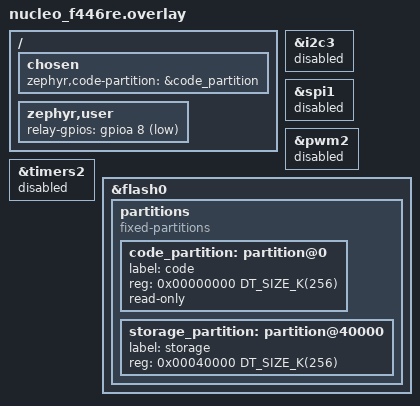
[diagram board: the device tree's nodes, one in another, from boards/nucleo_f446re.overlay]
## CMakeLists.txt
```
cmake_minimum_required(VERSION 3.20.0)
find_package(Zephyr REQUIRED HINTS $ENV{ZEPHYR_BASE})
project(grid_monitor)

target_sources(app PRIVATE
	src/main.c
	src/cfg.c
	src/cycle.c
	src/dsp.c
	src/fft_port.c
	src/sampler.c
	src/protect.c
	src/dsp_task.c
	src/logstore.c
	src/telemetry.c
	src/grid_shell.c
)
target_include_directories(app PRIVATE src)
```

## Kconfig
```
# Application Kconfig: pull in the STM32 HAL modules that src/sampler.c calls
# directly. These HAL symbols have no prompt, so they can only be selected,
# not set in prj.conf.

mainmenu "Grid Monitor"

config GRID_USES_STM32_HAL
	bool
	default y
	select USE_STM32_HAL_ADC
	select USE_STM32_HAL_ADC_EX
	select USE_STM32_HAL_DMA
	select USE_STM32_HAL_DMA_EX
	select USE_STM32_HAL_TIM
	select USE_STM32_HAL_TIM_EX
	select USE_STM32_HAL_GPIO

source "Kconfig.zephyr"
```

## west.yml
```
# West manifest: lets a teammate create the whole workspace with 3 commands.
#   west init -l grid_monitor
#   west update
# It pins Zephyr and fetches only the modules this project needs
# (the full Zephyr module set is several GB).
manifest:
  remotes:
    - name: zephyrproject-rtos
      url-base: https://github.com/zephyrproject-rtos
  projects:
    - name: zephyr
      remote: zephyrproject-rtos
      revision: v4.2.0
      import:
        name-allowlist:
          - cmsis
          - cmsis_6
          - cmsis-dsp
          - hal_stm32
  self:
    path: grid_monitor
```

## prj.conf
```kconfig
# ---- floating point on the Cortex-M4F, shared by several threads ----
CONFIG_FPU=y
CONFIG_FPU_SHARING=y
CONFIG_CBPRINTF_FP_SUPPORT=y

# (STM32 HAL modules are selected in the Kconfig file of this app)

# ---- CMSIS-DSP (real FFT) ----
CONFIG_CMSIS_DSP=y
CONFIG_CMSIS_DSP_TRANSFORM=y

# ---- message passing between threads ----
CONFIG_ZBUS=y
CONFIG_ZBUS_MSG_SUBSCRIBER=y

# ---- flash log (NVS) ----
CONFIG_FLASH=y
CONFIG_FLASH_MAP=y
CONFIG_FLASH_PAGE_LAYOUT=y
CONFIG_NVS=y
CONFIG_CRC=y

# ---- UART shell, kernel inspection ("kernel threads") ----
CONFIG_SHELL=y
CONFIG_KERNEL_SHELL=y
CONFIG_THREAD_MONITOR=y
CONFIG_THREAD_NAME=y
CONFIG_THREAD_STACK_INFO=y
CONFIG_INIT_STACKS=y
CONFIG_THREAD_RUNTIME_STATS=y
CONFIG_SHELL_THREAD_PRIORITY_OVERRIDE=y
CONFIG_SHELL_THREAD_PRIORITY=5
CONFIG_SHELL_STACK_SIZE=3072

# ---- logging goes through the shell ----
CONFIG_LOG=y
CONFIG_MAIN_STACK_SIZE=2048

# ---- keep the firmware inside the 256 KB "code" partition (see overlay) ----
CONFIG_USE_DT_CODE_PARTITION=y

# ---- zbus: fixed-size buffers, no heap use from the protection thread ----
CONFIG_ZBUS_MSG_SUBSCRIBER_BUF_ALLOC_STATIC=y
CONFIG_ZBUS_MSG_SUBSCRIBER_NET_BUF_STATIC_DATA_SIZE=64
CONFIG_ZBUS_MSG_SUBSCRIBER_NET_BUF_POOL_SIZE=16
```

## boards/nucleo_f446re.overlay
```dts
/*
 * Board overlay for the Grid Monitor on the STM32 Nucleo-F446RE.
 *
 *  PA0  voltage input (ADC1 IN0)      - set up directly by src/sampler.c
 *  PA1  current input (ADC2 IN1)      - set up directly by src/sampler.c
 *
 * Relay module (active-low, 5V coil) connected DIRECTLY to PA8 (D7) -
 * NO external transistor or MOSFET.
 * PA8 LOW  (0 V) = relay IN LOW  = relay energised (load ON)
 * PA8 HIGH (3.3V) = relay IN HIGH = relay off (load OFF)
 * GPIO_ACTIVE_LOW tells Zephyr: gpio_pin_set(relay, 1) drives PA8 LOW.
 *
 *  PA5  LD2 on-board LED              - from the board's led0 alias
 *  USART2 (PA2/PA3) 115200 baud       - shell and logs through ST-LINK
 */

/* Free the pins and timer we need by switching off board peripherals
 * that would otherwise claim them. */
/delete-node/ &boot_partition;
/delete-node/ &storage_partition;
/delete-node/ &slot0_partition;
/delete-node/ &slot1_partition;
/delete-node/ &scratch_partition;

/ {
	chosen {
		zephyr,code-partition = &code_partition;
	};

	zephyr,user {
    /*
     	* Direct connection to active-low 5V relay module.
     	* PA8 LOW  = relay ON
     	* PA8 HIGH = relay OFF
     	*/
    	relay-gpios = <&gpioa 8 GPIO_ACTIVE_LOW>;
	};
};

&i2c3  { status = "disabled"; };   /* uses PA8 */
&spi1  { status = "disabled"; };   /* uses PA5 */
&pwm2  { status = "disabled"; };
&timers2 { status = "disabled"; }; /* TIM2 is the ADC sample clock */

/*
 * Flash layout (512 KB): firmware in the first 256 KB, two 128 KB sectors at
 * the end for the NVS fault log and saved settings.
 */
&flash0 {
	partitions {
		compatible = "fixed-partitions";
		#address-cells = <1>;
		#size-cells = <1>;

		code_partition: partition@0 {
			label = "code";
			reg = <0x00000000 DT_SIZE_K(256)>;
			read-only;
		};

		storage_partition: partition@40000 {
			label = "storage";
			reg = <0x00040000 DT_SIZE_K(256)>;
		};
	};
};
```

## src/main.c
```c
/*
 * Zephyr OS Smart Grid - Micro-PMU and NILM load monitor.
 * main() only initialises the pieces; the work happens in three threads:
 *   protection (prio 0)  protect.c
 *   dsp / FFT  (prio 2)  dsp_task.c
 *   telemetry  (prio 5)  telemetry.c   (+ the UART shell, also prio 5)
 */
#include <zephyr/kernel.h>
#include <zephyr/logging/log.h>
#include "app.h"
#include "sampler.h"
#include "protect.h"
#include "logstore.h"

LOG_MODULE_REGISTER(main, LOG_LEVEL_INF);

int main(void)
{
	cfg_defaults(&g_cfg);
	int rc = protect_init();

	if (rc < 0) {
		LOG_ERR("Relay initialization failed: %d", rc);
		return rc;
	}

	if (logstore_init() == 0) {
		if (logstore_load_cfg(&g_cfg)) {
			LOG_INF("configuration loaded from flash");
		} else {
			LOG_INF("no saved configuration, using defaults");
		}
	}
	g_cfg.auto_on = 1;

	rc = sampler_init();

	if (rc) {
		LOG_ERR("sampler init failed (%d) - relay stays OFF", rc);
		return rc;
	}
	rc = sampler_start();
	if (rc) {
		LOG_ERR("sampler start failed (%d) - relay stays OFF", rc);
		return rc;
	}
	protect_start();
	LOG_INF("Grid monitor running. Type: grid help");
	return 0;
}
```

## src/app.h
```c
/*
 * app.h - shared types and constants for the Grid Monitor (Micro-PMU + NILM)
 */
#ifndef APP_H_
#define APP_H_

#include <stdint.h>
#include <stdbool.h>

/* ---- sampling geometry ------------------------------------------------ */
#define BLOCK_SAMPLES   16u      /* samples per DMA half-buffer (1.5625 ms)   */
#define RING_SAMPLES    4096u    /* raw sample ring (must be a power of two)  */
#define FFT_N           2048u    /* FFT window: 10 cycles of 50 Hz @ 10.24 kHz*/
#define FS_NOMINAL_HZ   10240.0f

/* ---- appliance classes ------------------------------------------------- */
enum load_class {
	LOAD_UNKNOWN = 0,
	LOAD_NONE,
	LOAD_RESISTIVE,
	LOAD_SMPS,
	LOAD_MOTOR,
	LOAD_CLASS_COUNT
};

/* ---- trip reasons ------------------------------------------------------ */
enum trip_reason {
	TRIP_NONE = 0,
	TRIP_PEAK,      /* instantaneous over-current (or ADC clipping)  */
	TRIP_RMS,       /* RMS over-current for several cycles           */
	TRIP_THERMAL,   /* long mild overload (I^2 t style)              */
	TRIP_POLICY,    /* appliance class not allowed                   */
	TRIP_MANUAL,    /* operator command                              */
	TRIP_SENSOR,    /* sampling stopped (fail-safe)                  */
	TRIP_VOLTAGE,   /* over/under voltage                            */
	TRIP_REASON_COUNT
};

const char *load_class_str(enum load_class c);
const char *trip_reason_str(enum trip_reason r);

/* ---- one measurement per mains cycle ------------------------------------ */
struct cycle_metrics {
	uint32_t seq;
	uint32_t t_ms;
	bool     valid;      /* false = no usable mains signal                */
	uint16_t n;          /* samples in this cycle                         */
	float    freq_hz;
	float    vrms, irms; /* real units (V, A)                             */
	float    p, s, q;    /* W, VA, var (q = sqrt(S^2-P^2), non-active)    */
	float    pf;         /* signed: P / S                                 */
	float    ipeak;      /* A                                             */
	float    v_cnt_rms;  /* rms in ADC counts (for calibration)           */
	float    i_cnt_rms;
	float    ofs_v, ofs_i;
};

/* ---- features from one FFT window ------------------------------------- */
struct features {
	bool     valid;
	uint32_t t_ms;
	float    i1;         /* fundamental current, A rms                    */
	float    h3, h5, h7; /* harmonic ratios I_n / I_1                     */
	float    thd;        /* ratio (1.0 = 100 %)                           */
	float    phi1_deg;   /* + = current lags voltage                      */
	float    cosphi1;
	float    q1;         /* fundamental reactive power, var               */
	float    vrms1;      /* fundamental voltage, V rms                    */
	float    crest, form;
};

/* ---- fault log record (stored in flash) ------------------------------- */
struct fault_event {
	uint32_t t_ms;
	uint32_t seq;
	uint8_t  reason;
	uint8_t  load_class;
	uint16_t peak_counts;   /* ADC counts, set by the fast ISR trip path */
	float    value;      /* the number that caused the trip               */
	float    irms, ipeak, vrms, p, thd;
};

/* ---- persistent configuration ----------------------------------------- */
#define CFG_MAGIC    0x47524944u   /* 'GRID' */
#define CFG_VERSION  2u

struct app_cfg {
	uint32_t magic;
	uint32_t version;
	/* calibration */
	float    k_v;           /* volts per ADC count                         */
	float    k_i1;          /* load amps per ADC count with ONE turn       */
	uint32_t turns;         /* wire turns through the clamp                */
	uint32_t invert_i;      /* 1 = clamp fitted backwards                  */
	uint32_t auto_on;       /* 1 = energise relay after warm-up            */
	/* protection */
	float    i_peak_limit;  /* A, instantaneous                            */
	float    i_rms_limit;   /* A rms                                       */
	uint32_t rms_cycles;    /* cycles above limit before trip              */
	float    i_rated;       /* A rms, thermal model                        */
	float    e_max;         /* A^2*s, thermal trip level                   */
	float    v_high;        /* V rms, 0 = disabled                         */
	float    v_low;         /* V rms, 0 = disabled                         */
	uint32_t banned_mask;   /* bit (1<<class) set = class not allowed      */
	/* classifier (ILLUSTRATIVE - tune from real measurements) */
	float    t_min_irms;    /* below this = no load                        */
	float    t_thd_res;     /* resistive: THD below                        */
	float    t_pf_res;      /* resistive: |PF| at least                    */
	float    t_thd_smps;    /* SMPS: THD at least                          */
	float    t_h3_smps;     /* SMPS: h3 at least                           */
	float    t_inrush_motor;/* motor: inrush ratio at least                */
	float    t_event_w;     /* step in P that counts as an event           */
	float    t_eps_a;       /* steady-state tolerance on Irms              */
	uint32_t steady_cycles; /* cycles of steady Irms before FFT            */
	uint32_t fft_interval;  /* cycles between FFT runs while steady        */
	uint32_t debounce;      /* identical results needed to accept a class  */
	uint32_t thd_max_h;     /* highest harmonic in THD (<= 50)             */
	uint32_t crc;           /* must stay last                              */
};

extern struct app_cfg g_cfg;

void  cfg_defaults(struct app_cfg *c);
float cfg_ki(const struct app_cfg *c);   /* load amps per ADC count */

#endif /* APP_H_ */
```

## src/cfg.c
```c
#include <string.h>
#include "app.h"

struct app_cfg g_cfg;

static const char *const class_names[LOAD_CLASS_COUNT] = {
	"Unknown", "No load", "Resistive", "Switch-mode supply", "Motor/inductive"
};
static const char *const reason_names[TRIP_REASON_COUNT] = {
	"none", "peak current", "rms current", "thermal overload",
	"policy (banned appliance)", "manual", "sensor/sampling lost", "voltage"
};

const char *load_class_str(enum load_class c)
{
	return (c < LOAD_CLASS_COUNT) ? class_names[c] : "?";
}

const char *trip_reason_str(enum trip_reason r)
{
	return (r < TRIP_REASON_COUNT) ? reason_names[r] : "?";
}

void cfg_defaults(struct app_cfg *c)
{
	memset(c, 0, sizeof(*c));
	c->magic         = CFG_MAGIC;
	c->version       = CFG_VERSION;
	/* PLACEHOLDER: run "grid cal v 7.071" for 20.00 Vpp (50 Hz) AFG sine. */
	c->k_v           = 0.33f;
	/* (3.3 V / 4096) / (0.110 V per A) for a 220 ohm burden, 1 turn */
	c->k_i1          = 0.007324f;
	c->turns         = 1;
	c->invert_i      = 0;
	c->auto_on       = 1;
	c->i_peak_limit  = 14.0f;
	c->i_rms_limit   = 8.0f;
	c->rms_cycles    = 3;
	c->i_rated       = 6.0f;
	c->e_max         = 60.0f;
	c->v_high        = 0.0f;
	c->v_low         = 0.0f;
	c->banned_mask   = 0;
	c->t_min_irms    = 0.080f;
	c->t_thd_res     = 0.20f;
	c->t_pf_res      = 0.90f;
	c->t_thd_smps    = 0.20f;
	c->t_h3_smps     = 0.10f;
	c->t_inrush_motor = 1.6f;
	c->t_event_w     = 0.20f;
	c->t_eps_a       = 0.035f;
	c->steady_cycles = 3;
	c->fft_interval  = 10;
	c->debounce      = 3;
	c->thd_max_h     = 50;
}

float cfg_ki(const struct app_cfg *c)
{
	uint32_t t = c->turns ? c->turns : 1;

	return c->k_i1 / (float)t;
}
```

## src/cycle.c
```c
#include <math.h>
#include <string.h>
#include "cycle.h"

static void reset_cur(struct cycle_det *d)
{
	memset(&d->cur, 0, sizeof(d->cur));
	d->cur.imax = -1;
	d->cur.imin = 0x7fffffff;
}

void cycle_init(struct cycle_det *d)
{
	memset(d, 0, sizeof(*d));
	d->ofs_v = 2048.0f;
	d->ofs_i = 2048.0f;
	reset_cur(d);
}

static void accumulate(struct cycle_raw *c, uint16_t v, uint16_t i)
{
	c->n++;
	c->sv += v;
	c->si += i;
	c->svv += (int64_t)v * v;
	c->sii += (int64_t)i * i;
	c->svi += (int64_t)v * i;
	if ((int32_t)i > c->imax) {
		c->imax = i;
	}
	if ((int32_t)i < c->imin) {
		c->imin = i;
	}
}

enum cyc_ev cycle_push(struct cycle_det *d, uint16_t v, uint16_t i,
		       struct cycle_raw *out)
{
	enum cyc_ev ev = CYC_NONE;

	/* Phase 1: measure the bias (about 2048 counts) over ~10 cycles. */
	if (!d->warm_done) {
		d->warm_sv += v;
		d->warm_si += i;
		if (++d->warm_n >= CYC_WARM_SAMPLES) {
			d->ofs_v = (float)d->warm_sv / (float)d->warm_n;
			d->ofs_i = (float)d->warm_si / (float)d->warm_n;
			d->warm_done = true;
		}
		return CYC_NONE;
	}

	float x = (float)v - d->ofs_v;

	d->since_cross++;

	if (x <= -(float)CYC_HYST) {
		d->armed = true;
	} else if (d->armed && x >= 0.0f) {
		/* rising zero crossing: this sample starts a new cycle */
		d->armed = false;
		if (d->in_cycle && d->cur.n >= CYC_N_MIN && d->cur.n <= CYC_N_MAX) {
			*out = d->cur;
			ev = CYC_DONE;
			/* the mean over one full cycle IS the bias; smooth it */
			float mv = (float)((double)d->cur.sv / d->cur.n);
			float mi = (float)((double)d->cur.si / d->cur.n);

			d->ofs_v += 0.25f * (mv - d->ofs_v);
			d->ofs_i += 0.25f * (mi - d->ofs_i);
		}
		d->since_cross = 1;
		reset_cur(d);
		d->in_cycle = true;
	} else if (d->since_cross > CYC_NOSIG_SAMPLES) {
		d->since_cross = 0;
		d->armed = false;
		d->in_cycle = false;
		reset_cur(d);
		ev = CYC_NOSIG;
	}

	if (d->in_cycle) {
		accumulate(&d->cur, v, i);
	}
	return ev;
}

void cycle_finish(const struct cycle_raw *r, const struct app_cfg *c,
		  float fs, struct cycle_metrics *m)
{
	double n  = (double)r->n;
	double mv = (double)r->sv / n;
	double mi = (double)r->si / n;
	double vv = (double)r->svv / n - mv * mv;
	double ii = (double)r->sii / n - mi * mi;
	double vi = (double)r->svi / n - mv * mi;

	if (vv < 0.0) {
		vv = 0.0;
	}
	if (ii < 0.0) {
		ii = 0.0;
	}

	double kv = c->k_v;
	double ki = cfg_ki(c);
	double vrms = sqrt(vv) * kv;
	double irms = sqrt(ii) * ki;
	double p = vi * kv * ki * (c->invert_i ? -1.0 : 1.0);
	double s = vrms * irms;
	double pf = (s > 1e-9) ? p / s : 0.0;
	double q2 = s * s - p * p;
	double dpk = (double)r->imax - mi;

	if (mi - (double)r->imin > dpk) {
		dpk = mi - (double)r->imin;
	}
	if (pf > 1.0) {
		pf = 1.0;
	}
	if (pf < -1.0) {
		pf = -1.0;
	}

	m->valid     = true;
	m->n         = (uint16_t)r->n;
	m->freq_hz   = fs / (float)r->n;
	m->vrms      = (float)vrms;
	m->irms      = (float)irms;
	m->p         = (float)p;
	m->s         = (float)s;
	m->q         = (float)sqrt(q2 > 0.0 ? q2 : 0.0);
	m->pf        = (float)pf;
	m->ipeak     = (float)(dpk * ki);
	m->v_cnt_rms = (float)sqrt(vv);
	m->i_cnt_rms = (float)sqrt(ii);
	m->ofs_v     = (float)mv;
	m->ofs_i     = (float)mi;
}
```

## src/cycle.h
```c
/*
 * cycle.h - mains-cycle detector and per-cycle power maths.
 * Pure C: no Zephyr or hardware dependencies, so it is unit-tested on a PC.
 */
#ifndef CYCLE_H_
#define CYCLE_H_

#include <stdint.h>
#include <stdbool.h>
#include "app.h"

#define CYC_WARM_SAMPLES   2048   /* initial offset measurement           */
#define CYC_HYST           10     /* counts below zero needed to re-arm   */
#define CYC_NOSIG_SAMPLES  600    /* ~58 ms without a crossing = no mains */
#define CYC_N_MIN          150    /* 68 Hz                                */
#define CYC_N_MAX          260    /* 39 Hz                                */

struct cycle_raw {
	uint32_t n;
	int64_t  sv, si;       /* sums of raw counts                          */
	int64_t  svv, sii, svi;
	int32_t  imax, imin;
};

struct cycle_det {
	bool     warm_done;
	uint32_t warm_n;
	int64_t  warm_sv, warm_si;
	float    ofs_v, ofs_i;
	bool     armed, in_cycle;
	uint32_t since_cross;
	struct cycle_raw cur;
};

enum cyc_ev { CYC_NONE = 0, CYC_DONE, CYC_NOSIG };

void cycle_init(struct cycle_det *d);

/* Feed one simultaneous (voltage, current) sample pair of raw ADC counts. */
enum cyc_ev cycle_push(struct cycle_det *d, uint16_t v, uint16_t i,
		       struct cycle_raw *out);

/* Turn raw sums into real units. fs = actual sampling rate in Hz. */
void cycle_finish(const struct cycle_raw *r, const struct app_cfg *c,
		  float fs, struct cycle_metrics *m);

#endif
```

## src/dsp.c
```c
#include <math.h>
#include <string.h>
#include "dsp.h"

#ifndef M_PI
#define M_PI 3.14159265358979323846
#endif

static float hann[FFT_N];
static float wk_in[FFT_N];
static float wk_out[FFT_N];

void dsp_init(void)
{
	for (uint32_t n = 0; n < FFT_N; n++) {
		hann[n] = 0.5f * (1.0f - cosf(2.0f * (float)M_PI * (float)n /
					      (float)(FFT_N - 1)));
	}
	fft_port_init();
}

static inline float bin_mag(const float *X, uint32_t k)
{
	return hypotf(X[2 * k], X[2 * k + 1]);
}

/* largest magnitude among bins k-1, k, k+1 */
static uint32_t peak_bin(const float *X, uint32_t k)
{
	uint32_t best = k;
	float bm = bin_mag(X, k);

	if (k > 1 && bin_mag(X, k - 1) > bm) {
		best = k - 1;
		bm = bin_mag(X, k - 1);
	}
	if (k + 1 < FFT_N / 2 && bin_mag(X, k + 1) > bm) {
		best = k + 1;
	}
	return best;
}

/* amplitude (counts, peak) of a Hann-windowed real FFT bin */
static inline float amp(const float *X, uint32_t k)
{
	return 4.0f * bin_mag(X, k) / (float)FFT_N;
}

bool dsp_features(const uint16_t *v, const uint16_t *i, const struct app_cfg *c,
		  struct features *f)
{
	memset(f, 0, sizeof(*f));

	/* ---- time-domain stats of the current (crest / form factor) ---- */
	double sv = 0, si = 0;

	for (uint32_t n = 0; n < FFT_N; n++) {
		sv += v[n];
		si += i[n];
	}
	float mv = (float)(sv / FFT_N);
	float mi = (float)(si / FFT_N);
	double ss = 0.0, sabs = 0.0;
	float pk = 0;

	for (uint32_t n = 0; n < FFT_N; n++) {
		float d = (float)i[n] - mi;

		ss += (double)d * (double)d;
		sabs += (double)fabsf(d);
		if (fabsf(d) > pk) {
			pk = fabsf(d);
		}
	}
	float irms_c = (float)sqrt(ss / FFT_N);
	float iabs_c = (float)(sabs / (double)FFT_N);

	if (irms_c < 1.0f) {
		return false;      /* less than one count of signal */
	}
	f->crest = pk / irms_c;
	f->form = (iabs_c > 0.0f) ? irms_c / iabs_c : 0.0f;

	float sgn = c->invert_i ? -1.0f : 1.0f;

	/* ---- voltage spectrum: find the fundamental bin ---- */
	for (uint32_t n = 0; n < FFT_N; n++) {
		wk_in[n] = ((float)v[n] - mv) * hann[n];
	}
	fft_port_rfft(wk_in, wk_out);

	uint32_t kf = 10;
	float best = 0;

	for (uint32_t k = 8; k <= 12; k++) {      /* 40 .. 60 Hz */
		float m = bin_mag(wk_out, k);

		if (m > best) {
			best = m;
			kf = k;
		}
	}
	if (best < 1.0f) {
		return false;      /* no voltage fundamental */
	}
	float vre = wk_out[2 * kf], vim = wk_out[2 * kf + 1];
	float v1_counts_peak = amp(wk_out, peak_bin(wk_out, kf));

	/* ---- current spectrum ---- */
	for (uint32_t n = 0; n < FFT_N; n++) {
		wk_in[n] = sgn * ((float)i[n] - mi) * hann[n];
	}
	fft_port_rfft(wk_in, wk_out);

	float ire = wk_out[2 * kf], iim = wk_out[2 * kf + 1];
	float i1_peak = amp(wk_out, peak_bin(wk_out, kf));

	if (i1_peak < 0.5f) {
		return false;
	}
	float ki = cfg_ki(c);
	const float r2 = 0.70710678f;

	f->i1 = i1_peak * r2 * ki;
	f->vrms1 = v1_counts_peak * r2 * c->k_v;

	float hsum2 = 0.0f;
	uint32_t H = c->thd_max_h;

	if (H < 2) {
		H = 2;
	}
	if (H > 50) {
		H = 50;
	}
	for (uint32_t h = 2; h <= H; h++) {
		uint32_t k = h * kf;

		if (k + 1 >= FFT_N / 2) {
			break;
		}
		float a = amp(wk_out, peak_bin(wk_out, k));

		hsum2 += a * a;
		if (h == 3) {
			f->h3 = a / i1_peak;
		} else if (h == 5) {
			f->h5 = a / i1_peak;
		} else if (h == 7) {
			f->h7 = a / i1_peak;
		}
	}
	f->thd = sqrtf(hsum2) / i1_peak;

	/* phase: positive = current lags voltage (inductive) */
	float phi = atan2f(vim, vre) - atan2f(iim, ire);

	while (phi > (float)M_PI) {
		phi -= 2.0f * (float)M_PI;
	}
	while (phi <= -(float)M_PI) {
		phi += 2.0f * (float)M_PI;
	}
	f->phi1_deg = phi * 180.0f / (float)M_PI;
	f->cosphi1 = cosf(phi);
	f->q1 = f->vrms1 * f->i1 * sinf(phi);
	f->valid = true;
	return true;
}

enum load_class dsp_classify(const struct app_cfg *c, float irms, float pf,
			     const struct features *f, float inrush)
{
	float apf = fabsf(pf);

	if (irms < c->t_min_irms) {
		return LOAD_NONE;
	}
	if (!f || !f->valid) {
		return LOAD_UNKNOWN;
	}
	if (f->thd >= c->t_thd_smps && f->h3 >= c->t_h3_smps) {
		return LOAD_SMPS;
	}
	if (f->thd < c->t_thd_res && apf >= c->t_pf_res) {
		return LOAD_RESISTIVE;
	}
	if (f->thd < c->t_thd_smps &&
	    (apf < c->t_pf_res || inrush >= c->t_inrush_motor)) {
		return LOAD_MOTOR;
	}
	return LOAD_UNKNOWN;
}

/* ====================== transient tracker ============================= */

void tracker_init(struct tracker *t)
{
	memset(t, 0, sizeof(*t));
	t->state = TR_SETTLING;
	t->inrush = 1.0f;
	t->accepted = LOAD_UNKNOWN;
	t->cand = LOAD_UNKNOWN;
}

static void start_event(struct tracker *t, const struct cycle_metrics *m)
{
	t->state = TR_SETTLING;
	t->steady_cnt = 0;
	t->peak_since_event = m->ipeak;
	t->cand = LOAD_UNKNOWN;
	t->cand_cnt = 0;
}

void tracker_on_cycle(struct tracker *t, const struct app_cfg *c,
		      const struct cycle_metrics *m, struct tracker_out *out)
{
	memset(out, 0, sizeof(*out));
	if (!m->valid) {
		t->have_prev = false;
		t->state = TR_SETTLING;
		t->steady_cnt = 0;
		return;
	}

	float eps = c->t_eps_a;

	if (0.03f * m->irms > eps) {
		eps = 0.03f * m->irms;
	}

	if (!t->have_prev) {
		t->have_prev = true;
		start_event(t, m);
		t->prev_irms = m->irms;
		t->prev_p = m->p;
		return;
	}

	/* "no load" detection (needs several cycles in a row) */
	if (m->irms < c->t_min_irms) {
		if (++t->none_cnt >= 5 && t->accepted != LOAD_NONE) {
			t->accepted = LOAD_NONE;
			out->class_changed = true;
		}
	} else {
		t->none_cnt = 0;
	}

	float dp = m->p - t->prev_p;

	if (fabsf(dp) > c->t_event_w) {
		start_event(t, m);
		out->event = true;
	} else if (t->state == TR_SETTLING) {
		if (m->ipeak > t->peak_since_event) {
			t->peak_since_event = m->ipeak;
		}
		if (fabsf(m->irms - t->prev_irms) < eps) {
			t->steady_cnt++;
		} else {
			t->steady_cnt = 0;
		}
		if (t->steady_cnt >= c->steady_cycles) {
			t->state = TR_STEADY;
			t->steady_irms = m->irms;
			t->inrush = (m->irms < c->t_min_irms || m->ipeak < 1e-3f) ?
				    1.0f : t->peak_since_event / m->ipeak;
			t->since_fft = c->fft_interval;   /* run FFT at once */
			out->need_fft = true;
		}
	} else { /* STEADY */
		float lim = 3.0f * eps;

		if (0.15f * t->steady_irms > lim) {
			lim = 0.15f * t->steady_irms;
		}
		if (fabsf(m->irms - t->steady_irms) > lim) {
			start_event(t, m);
			out->event = true;
		} else if (++t->since_fft >= c->fft_interval) {
			t->since_fft = 0;
			out->need_fft = true;
		}
	}
	t->prev_irms = m->irms;
	t->prev_p = m->p;
}

void tracker_on_features(struct tracker *t, const struct app_cfg *c,
			 const struct cycle_metrics *m, const struct features *f,
			 struct tracker_out *out)
{
	memset(out, 0, sizeof(*out));
	if (t->state != TR_STEADY) {
		return;     /* never classify during a transient */
	}
	enum load_class cls = dsp_classify(c, m->irms, m->pf, f, t->inrush);

	if (cls == t->cand) {
		t->cand_cnt++;
	} else {
		t->cand = cls;
		t->cand_cnt = 1;
	}
	if (t->cand_cnt >= c->debounce && t->cand != t->accepted) {
		t->accepted = t->cand;
		out->class_changed = true;
	}
}
```

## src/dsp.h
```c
/*
 * dsp.h - FFT features, appliance classifier and transient tracker.
 * Pure C (the FFT itself is behind fft_port.h) so it is unit-tested on a PC.
 */
#ifndef DSP_H_
#define DSP_H_

#include <stdint.h>
#include <stdbool.h>
#include "app.h"

/* The FFT back-end. Real FFT of FFT_N floats.
 * `in` may be destroyed. `out` is CMSIS "packed" format:
 *   out[0] = Re X[0], out[1] = Re X[N/2], then out[2k], out[2k+1] = Re, Im X[k]
 */
void fft_port_init(void);
void fft_port_rfft(float *in, float *out);

void dsp_init(void);

/* Compute features from FFT_N simultaneous raw samples. fs in Hz. */
bool dsp_features(const uint16_t *v, const uint16_t *i, const struct app_cfg *c,
		  struct features *f);

/* Pure classification rule. inrush = start-up peak / steady peak. */
enum load_class dsp_classify(const struct app_cfg *c, float irms, float pf,
			     const struct features *f, float inrush);

/* ---- transient tracker ------------------------------------------------ */
enum tr_state { TR_SETTLING = 0, TR_STEADY };

struct tracker {
	enum tr_state state;
	bool     have_prev;
	float    prev_irms, prev_p;
	float    steady_irms;
	uint32_t steady_cnt;
	uint32_t since_fft;
	uint32_t none_cnt;
	float    peak_since_event;
	float    inrush;
	enum load_class cand;
	uint32_t cand_cnt;
	enum load_class accepted;
};

struct tracker_out {
	bool need_fft;       /* run an FFT on the latest window now           */
	bool event;          /* a step change was detected                    */
	bool class_changed;  /* tracker->accepted changed                     */
};

void tracker_init(struct tracker *t);
void tracker_on_cycle(struct tracker *t, const struct app_cfg *c,
		      const struct cycle_metrics *m, struct tracker_out *out);
void tracker_on_features(struct tracker *t, const struct app_cfg *c,
			 const struct cycle_metrics *m, const struct features *f,
			 struct tracker_out *out);

#endif
```

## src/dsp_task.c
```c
/*
 * dsp_task.c - medium-priority thread: receives per-cycle metrics over zbus,
 * runs the transient tracker, takes a 2048-sample window when asked, computes
 * the FFT features and classifies the appliance.
 */
#include <zephyr/kernel.h>
#include <zephyr/logging/log.h>
#include "protect.h"
#include "sampler.h"
#include "dsp.h"

LOG_MODULE_REGISTER(dsp, LOG_LEVEL_INF);

ZBUS_MSG_SUBSCRIBER_DEFINE(dsp_sub);

static struct tracker trk;
static uint16_t wv[FFT_N], wi[FFT_N];

static void announce(const struct cycle_metrics *m)
{
	enum load_class cls = trk.accepted;

	protect_set_class(cls);
	LOG_INF("Load: %s  (Irms %d mA, P %d W, PF x100 %d)", load_class_str(cls),
		(int)(m->irms * 1000.0f), (int)m->p, (int)(m->pf * 100.0f));
	if ((g_cfg.banned_mask >> cls) & 1u) {
		LOG_WRN("Policy: appliance class not allowed -> trip");
		(void)protect_trip(TRIP_POLICY, (float)cls);
	}
}

static void dsp_thread(void *a, void *b, void *c)
{
	ARG_UNUSED(a); ARG_UNUSED(b); ARG_UNUSED(c);
	const struct zbus_channel *chan;
	struct cycle_metrics m;

	k_thread_name_set(NULL, "dsp_fft");
	dsp_init();
	tracker_init(&trk);

	for (;;) {
		if (zbus_sub_wait_msg(&dsp_sub, &chan, &m, K_FOREVER) != 0) {
			continue;
		}
		struct tracker_out o;

		tracker_on_cycle(&trk, &g_cfg, &m, &o);
		if (o.class_changed) {
			announce(&m);
		}
		if (o.need_fft && sampler_copy_window(wv, wi, FFT_N)) {
			struct features f;

			if (dsp_features(wv, wi, &g_cfg, &f)) {
				f.t_ms = k_uptime_get_32();
				protect_set_features(&f);
				protect_count_feature_run();
				tracker_on_features(&trk, &g_cfg, &m, &f, &o);
				if (o.class_changed) {
					announce(&m);
				}
			}
		}
	}
}

K_THREAD_DEFINE(dsp_tid, 4096, dsp_thread, NULL, NULL, NULL,
		K_PRIO_PREEMPT(2), 0, 0);
```

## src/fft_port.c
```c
/* FFT back-end using ARM CMSIS-DSP (Zephyr module cmsis-dsp). */
#include <arm_math.h>
#include "dsp.h"

static arm_rfft_fast_instance_f32 inst;

void fft_port_init(void)
{
	arm_rfft_fast_init_f32(&inst, FFT_N);
}

void fft_port_rfft(float *in, float *out)
{
	arm_rfft_fast_f32(&inst, in, out, 0);
}
```

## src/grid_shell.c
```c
/*
 * grid_shell.c - the "grid" command family on the UART shell.
 *   grid help
 */
#include <zephyr/kernel.h>
#include <zephyr/shell/shell.h>
#include <stdlib.h>
#include <string.h>
#include <stddef.h>
#include "app.h"
#include "protect.h"
#include "sampler.h"
#include "logstore.h"

/* ------------------------------------------------------------ status -- */

static int cmd_status(const struct shell *sh, size_t argc, char **argv)
{
	struct cycle_metrics m;
	struct features f;
	enum load_class cls;

	protect_get_snapshot(&m, &f, &cls);
	if (protect_is_tripped()) {
		shell_print(sh, "relay      : OFF - TRIPPED (%s). Use 'grid reset' after fixing the cause.",
			    trip_reason_str(protect_last_reason()));
	} else {
		shell_print(sh, "relay      : %s", protect_relay_state() ? "ON (load energised)" : "OFF");
	}
	if (!m.valid) {
		shell_print(sh, "mains      : no usable voltage signal yet");
	} else {
		shell_print(sh, "mains      : %.1f V rms, %.2f Hz", (double)m.vrms, (double)m.freq_hz);
		shell_print(sh, "current    : %.3f A rms, %.3f A peak", (double)m.irms, (double)m.ipeak);
		shell_print(sh, "power      : P %.1f W   S %.1f VA   Q(non-active) %.1f var   PF %.3f",
			    (double)m.p, (double)m.s, (double)m.q, (double)m.pf);
		if (m.p < -0.2f * m.s && m.s > 5.0f) {
			shell_warn(sh, "P is negative: clamp is probably backwards (try: grid cfg set invert_i 1)");
		}
	}
	shell_print(sh, "load class : %s", load_class_str(cls));
	if (f.valid) {
		shell_print(sh, "FFT        : I1 %.3f A  h3 %.2f h5 %.2f h7 %.2f  THD %.1f %%",
			    (double)f.i1, (double)f.h3, (double)f.h5, (double)f.h7, (double)(f.thd * 100.0f));
	}
	return 0;
}

static int cmd_feat(const struct shell *sh, size_t argc, char **argv)
{
	struct features f;

	protect_get_snapshot(NULL, &f, NULL);
	if (!f.valid) {
		shell_print(sh, "no FFT result yet (needs a steady load)");
		return 0;
	}
	shell_print(sh, "I1 %.4f A   Vrms1 %.1f V", (double)f.i1, (double)f.vrms1);
	shell_print(sh, "h3 %.3f  h5 %.3f  h7 %.3f  THD %.3f", (double)f.h3, (double)f.h5,
		    (double)f.h7, (double)f.thd);
	shell_print(sh, "phi1 %.1f deg (+ = current lags)  cos(phi1) %.3f  Q1 %.1f var",
		    (double)f.phi1_deg, (double)f.cosphi1, (double)f.q1);
	shell_print(sh, "crest %.2f  form %.2f", (double)f.crest, (double)f.form);
	return 0;
}

static int cmd_stats(const struct shell *sh, size_t argc, char **argv)
{
	struct sampler_stats s;
	struct protect_stats p;

	sampler_get_stats(&s);
	protect_get_stats(&p);
	shell_print(sh, "timer clock %u Hz, ARR %u, sampling rate %.3f Hz", s.timer_hz, s.arr,
		    (double)sampler_fs());
	shell_print(sh, "blocks %u  adc_err %u  dma_err %u  fast_trips %u", s.blocks, s.adc_err,
		    s.dma_err, s.fast_trips);
	shell_print(sh, "cycles %u  no-signal %u  ring overruns %u  fft runs %u", p.cycles, p.nosig,
		    p.overruns, p.feature_runs);
	return 0;
}

/* -------------------------------------------------------------- dump -- */

static uint16_t dv[FFT_N], di[FFT_N];

static int cmd_dump(const struct shell *sh, size_t argc, char **argv)
{
	uint32_t n = 1024;

	if (argc > 1) {
		n = (uint32_t)strtoul(argv[1], NULL, 10);
	}
	if (n < 16 || n > FFT_N) {
		shell_error(sh, "n must be 16..%u", (unsigned)FFT_N);
		return -EINVAL;
	}
	if (!sampler_copy_window(dv, di, n)) {
		shell_error(sh, "not enough samples yet, try again");
		return -EAGAIN;
	}
	shell_print(sh, "DUMP BEGIN fs=%.3f n=%u kv=%.6f ki=%.6f", (double)sampler_fs(),
		    (unsigned)n, (double)g_cfg.k_v, (double)cfg_ki(&g_cfg));
	for (uint32_t k = 0; k < n; k++) {
		shell_print(sh, "%u,%u", dv[k], di[k]);
	}
	shell_print(sh, "DUMP END");
	return 0;
}

/* --------------------------------------------------------- fault log -- */

static int cmd_fault_log(const struct shell *sh, size_t argc, char **argv)
{
	if (argc > 1 && strcmp(argv[1], "clear") == 0) {
		int rc = logstore_clear_faults();

		shell_print(sh, rc ? "clear failed (%d)" : "fault log cleared", rc);
		return rc;
	}
	uint32_t total = logstore_fault_count();

	shell_print(sh, "fault log: %u event(s) recorded in total (newest first)", total);
	for (uint32_t k = 0; k < 32; k++) {
		struct fault_event e;

		if (logstore_read_fault(k, &e) != 0) {
			break;
		}
		shell_print(sh, "#%u  t=%u ms  %s  | load=%s  value=%.3f  Irms=%.3f A  Ipeak=%.3f A  Vrms=%.1f V  P=%.1f W  THD=%.2f",
			    e.seq, e.t_ms, trip_reason_str((enum trip_reason)e.reason),
			    load_class_str((enum load_class)e.load_class), (double)e.value,
			    (double)e.irms, (double)e.ipeak, (double)e.vrms, (double)e.p, (double)e.thd);
	}
	return 0;
}

/* ------------------------------------------------------------- relay -- */

static int cmd_on(const struct shell *sh, size_t argc, char **argv)
{
	if (!protect_relay_on()) {
		shell_error(sh, "a trip is latched: use 'grid reset' after fixing the cause");
		return -EPERM;
	}
	shell_print(sh, "relay ON");
	return 0;
}

static int cmd_off(const struct shell *sh, size_t argc, char **argv)
{
	protect_relay_off();
	shell_print(sh, "relay OFF");
	return 0;
}

static int cmd_reset(const struct shell *sh, size_t argc, char **argv)
{
	protect_reset();
	shell_print(sh, "trip cleared, relay ON");
	return 0;
}

static int cmd_trip(const struct shell *sh, size_t argc, char **argv)
{
	(void)protect_trip(TRIP_MANUAL, 0.0f);
	shell_print(sh, "manual trip issued");
	return 0;
}

/* --------------------------------------------------------- calibrate -- */

static int cmd_cal(const struct shell *sh, size_t argc, char **argv)
{
	struct cycle_metrics m;

	if (argc != 3) {
		shell_error(sh, "usage: grid cal v <volts_rms> | grid cal i <amps_rms>");
		return -EINVAL;
	}
	float val = strtof(argv[2], NULL);

	protect_get_snapshot(&m, NULL, NULL);
	if (!m.valid || val <= 0.0f) {
		shell_error(sh, "need a valid mains signal and a positive value");
		return -EINVAL;
	}
	if (argv[1][0] == 'v') {
		if (m.v_cnt_rms < 5.0f) {
			shell_error(sh, "voltage signal too small");
			return -EINVAL;
		}
		g_cfg.k_v = val / m.v_cnt_rms;
		shell_print(sh, "k_v = %.6f V/count  (read the multimeter, then 'grid cfg save')",
			    (double)g_cfg.k_v);
	} else if (argv[1][0] == 'i') {
		if (m.i_cnt_rms < 2.0f) {
			shell_error(sh, "current signal too small - connect a known load");
			return -EINVAL;
		}
		g_cfg.k_i1 = val * (float)g_cfg.turns / m.i_cnt_rms;
		shell_print(sh, "k_i1 = %.6f A/count at 1 turn  (turns = %u)", (double)g_cfg.k_i1,
			    (unsigned)g_cfg.turns);
	} else {
		return -EINVAL;
	}
	return 0;
}

/* --------------------------------------------------------------- cfg -- */

enum ft { T_F, T_U };
struct field {
	const char *name;
	enum ft t;
	size_t off;
};
#define FF(n) { #n, T_F, offsetof(struct app_cfg, n) }
#define FU(n) { #n, T_U, offsetof(struct app_cfg, n) }

static const struct field fields[] = {
	FF(k_v), FF(k_i1), FU(turns), FU(invert_i), FU(auto_on),
	FF(i_peak_limit), FF(i_rms_limit), FU(rms_cycles), FF(i_rated), FF(e_max),
	FF(v_high), FF(v_low), FU(banned_mask),
	FF(t_min_irms), FF(t_thd_res), FF(t_pf_res), FF(t_thd_smps), FF(t_h3_smps),
	FF(t_inrush_motor), FF(t_event_w), FF(t_eps_a),
	FU(steady_cycles), FU(fft_interval), FU(debounce), FU(thd_max_h),
};

static void show_field(const struct shell *sh, const struct field *f)
{
	const uint8_t *base = (const uint8_t *)&g_cfg;

	if (f->t == T_F) {
		shell_print(sh, "  %-16s = %.6g", f->name, (double)*(const float *)(base + f->off));
	} else {
		shell_print(sh, "  %-16s = %u", f->name, *(const uint32_t *)(base + f->off));
	}
}

static int cmd_cfg(const struct shell *sh, size_t argc, char **argv)
{
	if (argc < 2) {
		shell_error(sh, "usage: grid cfg show | set <name> <value> | save | default");
		return -EINVAL;
	}
	if (strcmp(argv[1], "show") == 0) {
		for (size_t k = 0; k < ARRAY_SIZE(fields); k++) {
			show_field(sh, &fields[k]);
		}
		return 0;
	}
	if (strcmp(argv[1], "default") == 0) {
		cfg_defaults(&g_cfg);
		shell_print(sh, "defaults loaded (not saved yet)");
		return 0;
	}
	if (strcmp(argv[1], "save") == 0) {
		int rc = logstore_save_cfg(&g_cfg);

		shell_print(sh, rc ? "save failed (%d)" : "configuration saved to flash", rc);
		return rc;
	}
	if (strcmp(argv[1], "set") == 0 && argc == 4) {
		for (size_t k = 0; k < ARRAY_SIZE(fields); k++) {
			if (strcmp(argv[2], fields[k].name) != 0) {
				continue;
			}
			uint8_t *base = (uint8_t *)&g_cfg;

			if (fields[k].t == T_F) {
				*(float *)(base + fields[k].off) = strtof(argv[3], NULL);
			} else {
				*(uint32_t *)(base + fields[k].off) = (uint32_t)strtoul(argv[3], NULL, 0);
			}
			/* keep a few values inside safe ranges */
			if (g_cfg.turns < 1) { g_cfg.turns = 1; }
			if (g_cfg.turns > 50) { g_cfg.turns = 50; }
			if (g_cfg.thd_max_h < 2) { g_cfg.thd_max_h = 2; }
			if (g_cfg.thd_max_h > 50) { g_cfg.thd_max_h = 50; }
			if (g_cfg.steady_cycles < 2) { g_cfg.steady_cycles = 2; }
			if (g_cfg.fft_interval < 1) { g_cfg.fft_interval = 1; }
			if (g_cfg.debounce < 1) { g_cfg.debounce = 1; }
			if (g_cfg.rms_cycles < 1) { g_cfg.rms_cycles = 1; }
			show_field(sh, &fields[k]);
			return 0;
		}
		shell_error(sh, "unknown field '%s' (see: grid cfg show)", argv[2]);
		return -EINVAL;
	}
	shell_error(sh, "usage: grid cfg show | set <name> <value> | save | default");
	return -EINVAL;
}

/* ------------------------------------------------------------ policy -- */

static int class_from_name(const char *s)
{
	if (strcmp(s, "resistive") == 0) { return LOAD_RESISTIVE; }
	if (strcmp(s, "smps") == 0)      { return LOAD_SMPS; }
	if (strcmp(s, "motor") == 0)     { return LOAD_MOTOR; }
	if (strcmp(s, "unknown") == 0)   { return LOAD_UNKNOWN; }
	return -1;
}

static int cmd_policy(const struct shell *sh, size_t argc, char **argv)
{
	if (argc >= 2 && strcmp(argv[1], "clear") == 0) {
		g_cfg.banned_mask = 0;
	} else if (argc == 3 && (strcmp(argv[1], "ban") == 0 || strcmp(argv[1], "allow") == 0)) {
		int c = class_from_name(argv[2]);

		if (c < 0) {
			shell_error(sh, "class must be: resistive | smps | motor | unknown");
			return -EINVAL;
		}
		if (argv[1][0] == 'b') {
			g_cfg.banned_mask |= (1u << c);
		} else {
			g_cfg.banned_mask &= ~(1u << c);
		}
	} else if (argc != 2 || strcmp(argv[1], "show") != 0) {
		shell_error(sh, "usage: grid policy show | ban <class> | allow <class> | clear");
		return -EINVAL;
	}
	shell_print(sh, "banned classes:");
	bool any = false;

	for (int c = 0; c < LOAD_CLASS_COUNT; c++) {
		if ((g_cfg.banned_mask >> c) & 1u) {
			shell_print(sh, "  %s", load_class_str((enum load_class)c));
			any = true;
		}
	}
	if (!any) {
		shell_print(sh, "  (none)");
	}
	return 0;
}

/* -------------------------------------------------------------- help -- */

static int cmd_help(const struct shell *sh, size_t argc, char **argv)
{
	shell_print(sh,
		"grid status              live power numbers, relay and load class\n"
		"grid feat                FFT features (harmonics, THD, phase)\n"
		"grid stats               sampler and thread statistics\n"
		"grid dump [n]            raw samples as CSV (for tools/analyze_dump.py)\n"
		"grid fault_log [clear]   trip history stored in flash\n"
		"grid on | off | reset    relay control (reset clears a latched trip)\n"
		"grid trip                manual trip (test)\n"
		"grid cal v <V>           calibrate voltage against a multimeter\n"
		"grid cal i <A>           calibrate current against a known load\n"
		"grid cfg show|set|save|default   settings and thresholds\n"
		"grid policy show|ban|allow|clear <resistive|smps|motor|unknown>\n"
		"kernel threads           thread priorities, stack and CPU use");
	return 0;
}

SHELL_STATIC_SUBCMD_SET_CREATE(sub_grid,
	SHELL_CMD_ARG(help, NULL, "list commands", cmd_help, 1, 0),
	SHELL_CMD_ARG(status, NULL, "live status", cmd_status, 1, 0),
	SHELL_CMD_ARG(feat, NULL, "FFT features", cmd_feat, 1, 0),
	SHELL_CMD_ARG(stats, NULL, "statistics", cmd_stats, 1, 0),
	SHELL_CMD_ARG(dump, NULL, "dump [n]: raw samples", cmd_dump, 1, 1),
	SHELL_CMD_ARG(fault_log, NULL, "fault_log [clear]", cmd_fault_log, 1, 1),
	SHELL_CMD_ARG(on, NULL, "relay on", cmd_on, 1, 0),
	SHELL_CMD_ARG(off, NULL, "relay off", cmd_off, 1, 0),
	SHELL_CMD_ARG(reset, NULL, "clear trip, relay on", cmd_reset, 1, 0),
	SHELL_CMD_ARG(trip, NULL, "manual trip", cmd_trip, 1, 0),
	SHELL_CMD_ARG(cal, NULL, "cal v|i <value>", cmd_cal, 3, 0),
	SHELL_CMD_ARG(cfg, NULL, "cfg show|set|save|default", cmd_cfg, 2, 2),
	SHELL_CMD_ARG(policy, NULL, "policy show|ban|allow|clear", cmd_policy, 2, 1),
	SHELL_SUBCMD_SET_END);

SHELL_CMD_REGISTER(grid, &sub_grid, "Grid monitor commands", NULL);
```

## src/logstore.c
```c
/*
 * logstore.c - configuration and fault log in internal flash using NVS.
 * Storage partition is defined in boards/nucleo_f446re.overlay.
 */
#include <zephyr/kernel.h>
#include <zephyr/device.h>
#include <zephyr/storage/flash_map.h>
#include <zephyr/drivers/flash.h>
#include <zephyr/fs/nvs.h>
#include <zephyr/sys/crc.h>
#include <zephyr/logging/log.h>
#include <stddef.h>
#include <string.h>
#include "logstore.h"

LOG_MODULE_REGISTER(logstore, LOG_LEVEL_INF);

#define ID_CFG     1
#define ID_COUNT   2
#define ID_FAULT0  16
#define FAULT_MAX  32

static struct nvs_fs fs;
static bool ready;
K_MUTEX_DEFINE(ls_lock);

int logstore_init(void)
{
	struct flash_pages_info info;

	fs.flash_device = FIXED_PARTITION_DEVICE(storage_partition);
	if (!device_is_ready(fs.flash_device)) {
		LOG_ERR("flash not ready");
		return -ENODEV;
	}
	fs.offset = FIXED_PARTITION_OFFSET(storage_partition);
	int rc = flash_get_page_info_by_offs(fs.flash_device, fs.offset, &info);

	if (rc) {
		LOG_ERR("page info %d", rc);
		return rc;
	}
	fs.sector_size = info.size;
	fs.sector_count = FIXED_PARTITION_SIZE(storage_partition) / info.size;

	rc = nvs_mount(&fs);
	if (rc) {
		LOG_WRN("nvs_mount failed (%d), formatting", rc);
		(void)nvs_clear(&fs);
		rc = nvs_mount(&fs);
	}
	if (rc) {
		LOG_ERR("nvs_mount failed (%d)", rc);
		return rc;
	}
	ready = true;
	LOG_INF("flash log ready (%u sectors of %u bytes)", (unsigned)fs.sector_count,
		(unsigned)fs.sector_size);
	return 0;
}

bool logstore_load_cfg(struct app_cfg *c)
{
	struct app_cfg t;

	if (!ready) {
		return false;
	}
	k_mutex_lock(&ls_lock, K_FOREVER);
	ssize_t n = nvs_read(&fs, ID_CFG, &t, sizeof(t));

	k_mutex_unlock(&ls_lock);
	if (n != (ssize_t)sizeof(t) || t.magic != CFG_MAGIC || t.version != CFG_VERSION ||
	    t.crc != crc32_ieee((const uint8_t *)&t, offsetof(struct app_cfg, crc))) {
		return false;
	}
	*c = t;
	return true;
}

int logstore_save_cfg(const struct app_cfg *c)
{
	struct app_cfg t = *c;

	if (!ready) {
		return -ENODEV;
	}
	t.magic = CFG_MAGIC;
	t.version = CFG_VERSION;
	t.crc = crc32_ieee((const uint8_t *)&t, offsetof(struct app_cfg, crc));
	k_mutex_lock(&ls_lock, K_FOREVER);
	ssize_t n = nvs_write(&fs, ID_CFG, &t, sizeof(t));

	k_mutex_unlock(&ls_lock);
	return (n < 0) ? (int)n : 0;
}

uint32_t logstore_fault_count(void)
{
	uint32_t cnt = 0;

	if (!ready) {
		return 0;
	}
	k_mutex_lock(&ls_lock, K_FOREVER);
	if (nvs_read(&fs, ID_COUNT, &cnt, sizeof(cnt)) != (ssize_t)sizeof(cnt)) {
		cnt = 0;
	}
	k_mutex_unlock(&ls_lock);
	return cnt;
}

int logstore_append_fault(struct fault_event *ev)
{
	if (!ready) {
		return -ENODEV;
	}
	uint32_t cnt = logstore_fault_count();

	ev->seq = cnt;
	k_mutex_lock(&ls_lock, K_FOREVER);
	ssize_t n = nvs_write(&fs, ID_FAULT0 + (cnt % FAULT_MAX), ev, sizeof(*ev));

	if (n >= 0) {
		cnt++;
		n = nvs_write(&fs, ID_COUNT, &cnt, sizeof(cnt));
	}
	k_mutex_unlock(&ls_lock);
	return (n < 0) ? (int)n : 0;
}

int logstore_read_fault(uint32_t k, struct fault_event *ev)
{
	uint32_t cnt = logstore_fault_count();

	if (k >= cnt || k >= FAULT_MAX) {
		return -ENOENT;
	}
	uint32_t seq = cnt - 1u - k;

	k_mutex_lock(&ls_lock, K_FOREVER);
	ssize_t n = nvs_read(&fs, ID_FAULT0 + (seq % FAULT_MAX), ev, sizeof(*ev));

	k_mutex_unlock(&ls_lock);
	return (n == (ssize_t)sizeof(*ev)) ? 0 : -EIO;
}

int logstore_clear_faults(void)
{
	uint32_t zero = 0;

	if (!ready) {
		return -ENODEV;
	}
	k_mutex_lock(&ls_lock, K_FOREVER);
	for (int i = 0; i < FAULT_MAX; i++) {
		(void)nvs_delete(&fs, ID_FAULT0 + i);
	}
	ssize_t n = nvs_write(&fs, ID_COUNT, &zero, sizeof(zero));

	k_mutex_unlock(&ls_lock);
	return (n < 0) ? (int)n : 0;
}
```

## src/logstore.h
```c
#ifndef LOGSTORE_H_
#define LOGSTORE_H_

#include <stdbool.h>
#include "app.h"

int      logstore_init(void);
bool     logstore_load_cfg(struct app_cfg *c);      /* false if none/invalid */
int      logstore_save_cfg(const struct app_cfg *c);
int      logstore_append_fault(struct fault_event *ev);
uint32_t logstore_fault_count(void);                /* total ever written   */
/* k = 0 is the newest entry. Returns 0 on success. */
int      logstore_read_fault(uint32_t k, struct fault_event *ev);
int      logstore_clear_faults(void);

#endif
```
